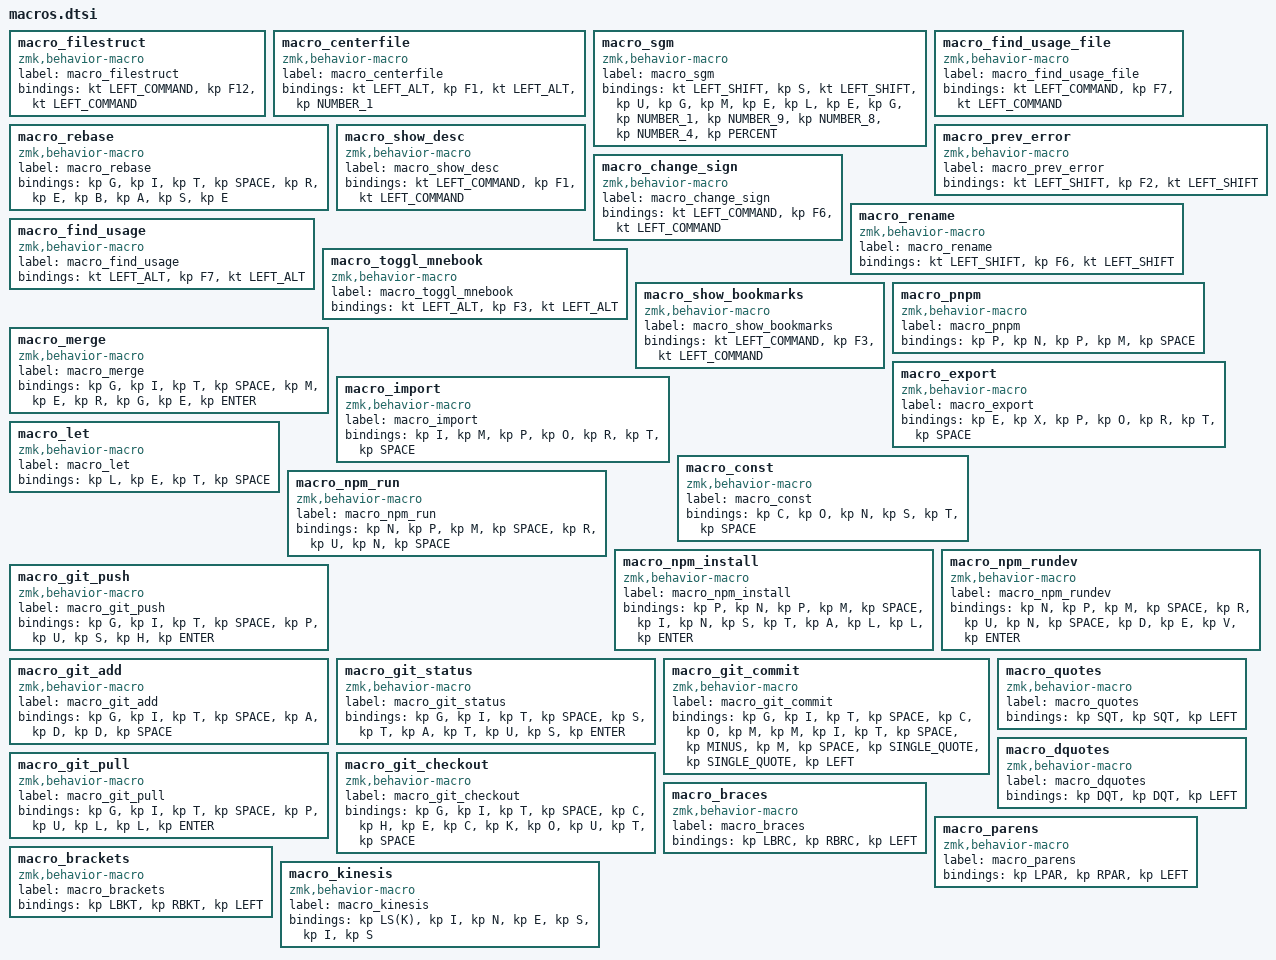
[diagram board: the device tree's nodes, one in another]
macro_filestruct: macro_filestruct{
compatible = "zmk,behavior-macro";
label = "macro_filestruct";
#binding-cells = <0>;
bindings = <&kt LEFT_COMMAND>, <&kp F12>, <&kt LEFT_COMMAND>;
};
macro_centerfile: macro_centerfile{
compatible = "zmk,behavior-macro";
label = "macro_centerfile";
#binding-cells = <0>;
bindings = <&kt LEFT_ALT>, <&kp F1>, <&kt LEFT_ALT>, <&kp NUMBER_1>;
};
macro_sgm: macro_sgm{
compatible = "zmk,behavior-macro";
label = "macro_sgm";
#binding-cells = <0>;
bindings = <&kt LEFT_SHIFT>, <&kp S>, <&kt LEFT_SHIFT>, <&kp U>, <&kp G>, <&kp M>, <&kp E>, <&kp L>, <&kp E>, <&kp G>, <&kp NUMBER_1>, <&kp NUMBER_9>, <&kp NUMBER_8>, <&kp NUMBER_4>, <&kp PERCENT>;
};
macro_find_usage_file: macro_find_usage_file{
compatible = "zmk,behavior-macro";
label = "macro_find_usage_file";
#binding-cells = <0>;
bindings = <&kt LEFT_COMMAND>, <&kp F7>, <&kt LEFT_COMMAND>;
};
macro_rebase: macro_rebase{
compatible = "zmk,behavior-macro";
label = "macro_rebase";
#binding-cells = <0>;
bindings = <&kp G>, <&kp I>, <&kp T>, <&kp SPACE>, <&kp R>, <&kp E>, <&kp B>, <&kp A>, <&kp S>, <&kp E>;
};
macro_prev_error: macro_prev_error{
compatible = "zmk,behavior-macro";
label = "macro_prev_error";
#binding-cells = <0>;
bindings = <&kt LEFT_SHIFT>, <&kp F2>, <&kt LEFT_SHIFT>;
};
macro_show_desc: macro_show_desc{
compatible = "zmk,behavior-macro";
label = "macro_show_desc";
#binding-cells = <0>;
bindings = <&kt LEFT_COMMAND>, <&kp F1>, <&kt LEFT_COMMAND>;
};
macro_change_sign: macro_change_sign{
compatible = "zmk,behavior-macro";
label = "macro_change_sign";
#binding-cells = <0>;
bindings = <&kt LEFT_COMMAND>, <&kp F6>, <&kt LEFT_COMMAND>;
};
macro_rename: macro_rename{
compatible = "zmk,behavior-macro";
label = "macro_rename";
#binding-cells = <0>;
bindings = <&kt LEFT_SHIFT>, <&kp F6>, <&kt LEFT_SHIFT>;
};
macro_find_usage: macro_find_usage{
compatible = "zmk,behavior-macro";
label = "macro_find_usage";
#binding-cells = <0>;
bindings = <&kt LEFT_ALT>, <&kp F7>, <&kt LEFT_ALT>;
};
macro_toggl_mnebook: macro_toggl_mnebook{
compatible = "zmk,behavior-macro";
label = "macro_toggl_mnebook";
#binding-cells = <0>;
bindings = <&kt LEFT_ALT>, <&kp F3>, <&kt LEFT_ALT>;
};
macro_show_bookmarks: macro_show_bookmarks{
compatible = "zmk,behavior-macro";
label = "macro_show_bookmarks";
#binding-cells = <0>;
bindings = <&kt LEFT_COMMAND>, <&kp F3>, <&kt LEFT_COMMAND>;
};
macro_pnpm: macro_pnpm{
compatible = "zmk,behavior-macro";
label = "macro_pnpm";
#binding-cells = <0>;
bindings = <&kp P>, <&kp N>, <&kp P>, <&kp M>, <&kp SPACE>;
};
macro_merge: macro_merge{
compatible = "zmk,behavior-macro";
label = "macro_merge";
#binding-cells = <0>;
bindings = <&kp G>, <&kp I>, <&kp T>, <&kp SPACE>, <&kp M>, <&kp E>, <&kp R>, <&kp G>, <&kp E>, <&kp ENTER>;
};
macro_export: macro_export{
compatible = "zmk,behavior-macro";
label = "macro_export";
#binding-cells = <0>;
bindings = <&kp E>, <&kp X>, <&kp P>, <&kp O>, <&kp R>, <&kp T>, <&kp SPACE>;
};
macro_import: macro_import{
compatible = "zmk,behavior-macro";
label = "macro_import";
#binding-cells = <0>;
bindings = <&kp I>, <&kp M>, <&kp P>, <&kp O>, <&kp R>, <&kp T>, <&kp SPACE>;
};
macro_let: macro_let{
compatible = "zmk,behavior-macro";
label = "macro_let";
#binding-cells = <0>;
bindings = <&kp L>, <&kp E>, <&kp T>, <&kp SPACE>;
};
macro_const: macro_const{
compatible = "zmk,behavior-macro";
label = "macro_const";
#binding-cells = <0>;
bindings = <&kp C>, <&kp O>, <&kp N>, <&kp S>, <&kp T>, <&kp SPACE>;
};
macro_npm_run: macro_npm_run{
compatible = "zmk,behavior-macro";
label = "macro_npm_run";
#binding-cells = <0>;
bindings = <&kp N>, <&kp P>, <&kp M>, <&kp SPACE>, <&kp R>, <&kp U>, <&kp N>, <&kp SPACE>;
};
macro_npm_install: macro_npm_install{
compatible = "zmk,behavior-macro";
label = "macro_npm_install";
#binding-cells = <0>;
bindings = <&kp P>, <&kp N>, <&kp P>, <&kp M>, <&kp SPACE>, <&kp I>, <&kp N>, <&kp S>, <&kp T>, <&kp A>, <&kp L>, <&kp L>, <&kp ENTER>;
};
macro_npm_rundev: macro_npm_rundev{
compatible = "zmk,behavior-macro";
label = "macro_npm_rundev";
#binding-cells = <0>;
bindings = <&kp N>, <&kp P>, <&kp M>, <&kp SPACE>, <&kp R>, <&kp U>, <&kp N>, <&kp SPACE>, <&kp D>, <&kp E>, <&kp V>, <&kp ENTER>;
};
macro_git_push: macro_git_push{
compatible = "zmk,behavior-macro";
label = "macro_git_push";
#binding-cells = <0>;
bindings = <&kp G>, <&kp I>, <&kp T>, <&kp SPACE>, <&kp P>, <&kp U>, <&kp S>, <&kp H>, <&kp ENTER>;
};
macro_git_add: macro_git_add{
compatible = "zmk,behavior-macro";
label = "macro_git_add";
#binding-cells = <0>;
bindings = <&kp G>, <&kp I>, <&kp T>, <&kp SPACE>, <&kp A>, <&kp D>, <&kp D>, <&kp SPACE>;
};
macro_git_status: macro_git_status{
compatible = "zmk,behavior-macro";
label = "macro_git_status";
#binding-cells = <0>;
bindings = <&kp G>, <&kp I>, <&kp T>, <&kp SPACE>, <&kp S>, <&kp T>, <&kp A>, <&kp T>, <&kp U>, <&kp S>, <&kp ENTER>;
};
macro_git_commit: macro_git_commit{
compatible = "zmk,behavior-macro";
label = "macro_git_commit";
#binding-cells = <0>;
bindings = <&kp G>, <&kp I>, <&kp T>, <&kp SPACE>, <&kp C>, <&kp O>, <&kp M>, <&kp M>, <&kp I>, <&kp T>, <&kp SPACE>, <&kp MINUS>, <&kp M>, <&kp SPACE>, <&kp SINGLE_QUOTE>, <&kp SINGLE_QUOTE>, <&kp LEFT>;
};
macro_git_pull: macro_git_pull{
compatible = "zmk,behavior-macro";
label = "macro_git_pull";
#binding-cells = <0>;
bindings = <&kp G>, <&kp I>, <&kp T>, <&kp SPACE>, <&kp P>, <&kp U>, <&kp L>, <&kp L>, <&kp ENTER>;
};
macro_git_checkout: macro_git_checkout{
compatible = "zmk,behavior-macro";
label = "macro_git_checkout";
#binding-cells = <0>;
bindings = <&kp G>, <&kp I>, <&kp T>, <&kp SPACE>, <&kp C>, <&kp H>, <&kp E>, <&kp C>, <&kp K>, <&kp O>, <&kp U>, <&kp T>, <&kp SPACE>;
};
macro_quotes: macro_quotes{
compatible = "zmk,behavior-macro";
label = "macro_quotes";
#binding-cells = <0>;
bindings = <&kp SQT>, <&kp SQT>, <&kp LEFT>;
};
macro_dquotes: macro_dquotes{
compatible = "zmk,behavior-macro";
label = "macro_dquotes";
#binding-cells = <0>;
bindings = <&kp DQT>, <&kp DQT>, <&kp LEFT>;
};
macro_braces: macro_braces{
compatible = "zmk,behavior-macro";
label = "macro_braces";
#binding-cells = <0>;
bindings = <&kp LBRC>, <&kp RBRC>, <&kp LEFT>;
};
macro_parens: macro_parens{
compatible = "zmk,behavior-macro";
label = "macro_parens";
#binding-cells = <0>;
bindings = <&kp LPAR>, <&kp RPAR>, <&kp LEFT>;
};
macro_brackets: macro_brackets{
compatible = "zmk,behavior-macro";
label = "macro_brackets";
#binding-cells = <0>;
bindings = <&kp LBKT>, <&kp RBKT>, <&kp LEFT>;
};
macro_kinesis: macro_kinesis{
compatible = "zmk,behavior-macro";
label = "macro_kinesis";
#binding-cells = <0>;
bindings = <&kp LS(K)>, <&kp I>, <&kp N>, <&kp E>, <&kp S>, <&kp I>, <&kp S>;
};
